# AT32F421xx register map
Vendor: Keil; Series: AT32F421; File version: 1.0
CPU: CM4 r0p1, little endian, no MPU, FPU, 4 interrupt priority bits
Registers are 32-bit, read-write, reset 0x0 unless marked. A register's access mark holds for its fields unless they carry their own. Offsets are from the block's base; [hi:lo] are bit positions; {n}, {i} and the like mark numbered series.

## SYSCFG — System configuration controller
Base 0x40010000
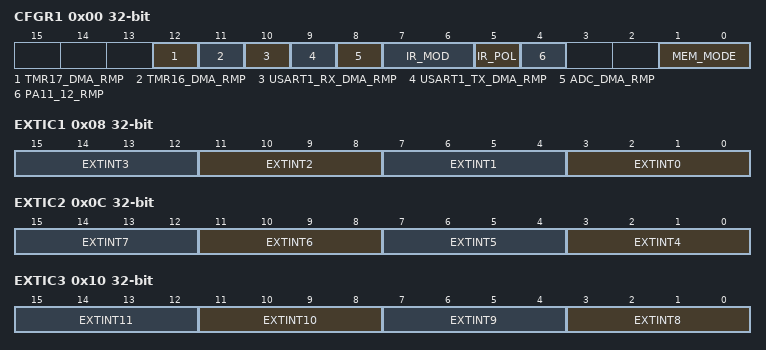
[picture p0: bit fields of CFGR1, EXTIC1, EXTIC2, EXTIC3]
0x00 CFGR1 — configuration register 1
  [12] TMR17_DMA_RMP — TMR17 DMA request remapping bit
  [11] TMR16_DMA_RMP — TMR16 DMA request remapping bit
  [10] USART1_RX_DMA_RMP — USART1_RX DMA request remapping bit
  [9] USART1_TX_DMA_RMP — USART1_TX DMA remapping bit
  [8] ADC_DMA_RMP — ADC DMA remapping bit
  [7:6] IR_MOD — IR mode ctrl bit
  [5] IR_POL — IR polarity ctrl bit
  [4] PA11_12_RMP — PA11/PA12 pins remapping bit
  [1:0] MEM_MODE — Memory mapping selection bits
0x08 EXTIC1 — external interrupt configuration register 1
  [4n+3:4n] EXTINT{n} (n=0..3) — EXTINT {n} configuration bits
0x0C EXTIC2 — external interrupt configuration register 2
  [4n-13:4n-16] EXTINT{n} (n=4..7) — EXTINT {n} configuration bits
0x10 EXTIC3 — external interrupt configuration register 3
  [4n-29:4n-32] EXTINT{n} (n=8..11) — EXTINT {n} configuration bits
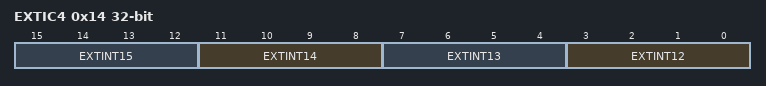
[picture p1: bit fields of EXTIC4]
0x14 EXTIC4 — external interrupt configuration register 4
  [4n-45:4n-48] EXTINT{n} (n=12..15) — EXTINT {n} configuration bits

## MCUDBG — Debug support
Base 0xE0042000
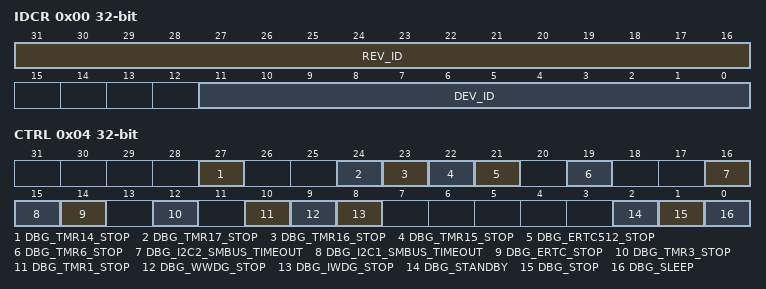
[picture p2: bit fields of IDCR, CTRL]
0x00 IDCR ro — MCUDBG_IDCODE
  [31:16] REV_ID, [11:0] DEV_ID
0x04 CTRL — MCUDBG_CTRL
  [27] DBG_TMR14_STOP
  [24] DBG_TMR17_STOP
  [23] DBG_TMR16_STOP
  [22] DBG_TMR15_STOP
  [21] DBG_ERTC512_STOP
  [19] DBG_TMR6_STOP
  [16] DBG_I2C2_SMBUS_TIMEOUT
  [15] DBG_I2C1_SMBUS_TIMEOUT
  [14] DBG_ERTC_STOP
  [12] DBG_TMR3_STOP — DBG_TIM3_STOP
  [10] DBG_TMR1_STOP — DBG_TIM1_STOP
  [9] DBG_WWDG_STOP
  [8] DBG_IWDG_STOP
  [2] DBG_STANDBY
  [1] DBG_STOP
  [0] DBG_SLEEP

## CRC — CRC calculation unit
Base 0x40023000
0x00 DT reset 0xFFFFFFFF — Data register
  [31:0] DR — Data Register
0x04 IDT — Independent Data register
  [7:0] IDR
0x08 CTRL — Control register
  [7:0] RESET — Reset bit

## NVIC — Nested Vectored Interrupt Controller
Base 0xE000E000
0x04 ICTR ro — Interrupt Controller Type Register
  [3:0] INTLINESNUM — Total number of interrupt lines in groups
0x100 ISER0 — Interrupt Set-Enable Register
  [31:0] SETENA
0x104 ISER1 — Interrupt Set-Enable Register
  [31:0] SETENA
0x180 ICER0 — Interrupt Clear-Enable Register
  [31:0] CLRENA
0x184 ICER1 — Interrupt Clear-Enable Register
  [31:0] CLRENA
0x200 ISPR0 — Interrupt Set-Pending Register
  [31:0] SETPEND
0x204 ISPR1 — Interrupt Set-Pending Register
  [31:0] SETPEND
0x280 ICPR0 — Interrupt Clear-Pending Register
  [31:0] CLRPEND
0x284 ICPR1 — Interrupt Clear-Pending Register
  [31:0] CLRPEND
0x300 IABR0 ro — Interrupt Active Bit Register
  [31:0] ACTIVE
0x304 IABR1 ro — Interrupt Active Bit Register
  [31:0] ACTIVE
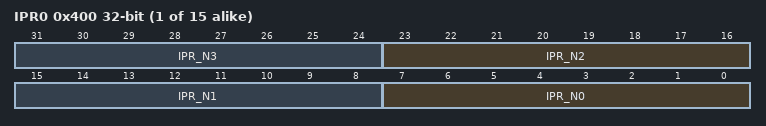
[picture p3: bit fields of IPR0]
{0x400+4i} IPR{i} (i=0..14) — Interrupt Priority Register
  [8n+7:8n] IPR_N{n} (n=0..3)
0xF00 STIR wo — Software Triggered Interrupt Register
  [8:0] INTID — interrupt to be triggered

## COMP — Compare
Base 0x4001001C
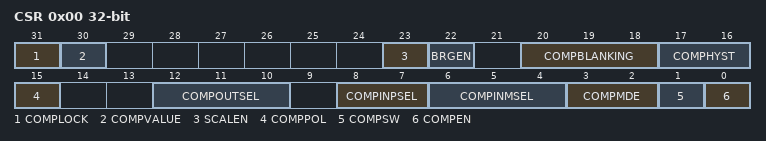
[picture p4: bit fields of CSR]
0x00 CSR — Comp control/status register
  [31] COMPLOCK — COMP_CSR1[15:0] register lock bit
  [30] COMPVALUE ro — Comparator output status bit
  [23] SCALEN — Comparator scalen bit
  [22] BRGEN — Comparator brgen bit
  [20:18] COMPBLANKING — Comparator blanking bit
  [17:16] COMPHYST — Comparator hysteresis bit
  [15] COMPPOL — Comparator polarity selection bit
  [12:10] COMPOUTSEL — Comparator output selection bit
  [8:7] COMPINPSEL — Comparator input selection bit
  [6:4] COMPINMSEL — Comparator inverting input selection
  [3:2] COMPMDE — Comparator mode
  [1] COMPSW — Comparator non inverting input DAC switch
  [0] COMPEN — Comparator enable bit
0x08 G_FILTER_EN
  [0] GFE — Glitch filter enable
0x0C HIGH_PULSE
  [5:0] H_PULSE_CNT — High pulse Count
0x10 LOW_PULSE
  [5:0] L_PULSE_CNT — Low pulse Count
